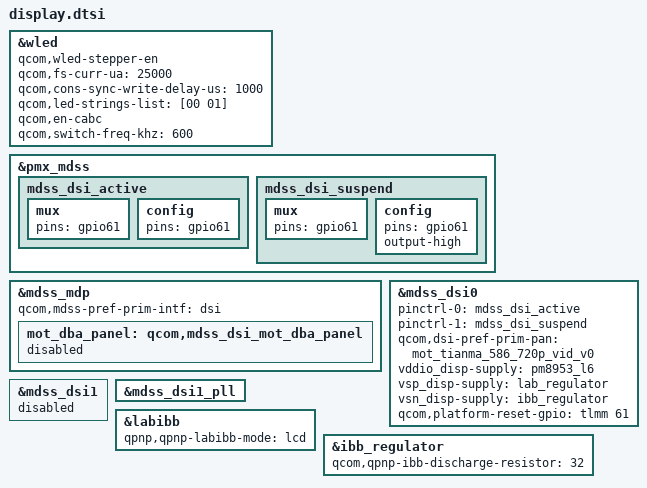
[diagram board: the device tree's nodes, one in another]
#include "dsi-panel/dsi-panel-mot-tianma-586-720p-vid.dtsi"
#include "dsi-panel/dsi-panel-mot-nova-586-hd-vid.dtsi

&wled {
	qcom,wled-stepper-en;
	qcom,fs-curr-ua = <25000>;
	qcom,cons-sync-write-delay-us = <1000>;
	qcom,led-strings-list = [00 01];
	qcom,en-cabc;
	qcom,switch-freq-khz = <600>;
};

&pmx_mdss {
	mdss_dsi_active {
		mux {
			pins = "gpio61";
		};

		config {
			pins = "gpio61";
		};
	};

	mdss_dsi_suspend {
		mux {
			pins = "gpio61";
		};

		config {
			pins = "gpio61";
			output-high;
		};
	};
};

&mdss_mdp {
	qcom,mdss-pref-prim-intf = "dsi";

	mot_dba_panel: qcom,mdss_dsi_mot_dba_panel{
		#include "dsi-panel/dsi-panel-mot-mod-fwvga-video-common.dtsi"
	};
};

&mdss_dsi0 {
	pinctrl-names = "mdss_default", "mdss_sleep";
	pinctrl-0 = <&mdss_dsi_active>;
	pinctrl-1 = <&mdss_dsi_suspend>;

	qcom,dsi-pref-prim-pan = <&mot_tianma_586_720p_vid_v0>;

	/delete-property/ vdd-supply;
	vddio_disp-supply = <&pm8953_l6>;
	vsp_disp-supply = <&lab_regulator>;
	vsn_disp-supply = <&ibb_regulator>;

	qcom,platform-reset-gpio = <&tlmm 61 0>;
};

&mdss_dsi1 {
	status = "disabled";
};

&mdss_dsi1_pll {
	/delete-property/ qcom,dsi-pll-ssc-en;
	/delete-property/ qcom,dsi-pll-ssc-mode;
};

&mot_dba_panel {
	status = "disabled";
};


/* display boost and inverting boost regulators */
&labibb {
	status = "ok";
	qpnp,qpnp-labibb-mode = "lcd";
};

&ibb_regulator {
	qcom,qpnp-ibb-discharge-resistor = <32>;
};
